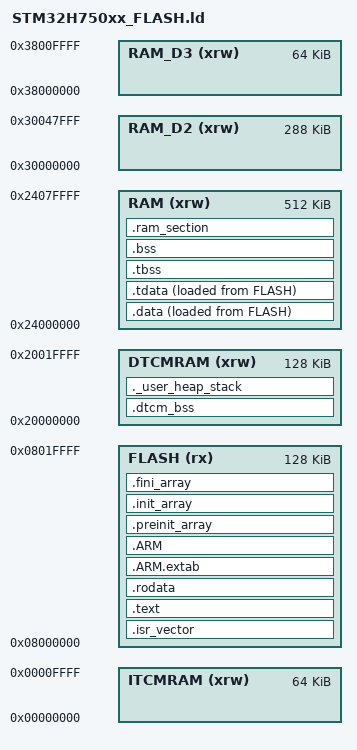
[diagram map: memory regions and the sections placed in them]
/*
******************************************************************************
**

**  File        : LinkerScript.ld
**
**  Author		: STM32CubeMX
**
**  Abstract    : Linker script for STM32H750VBTx series
**                128Kbytes FLASH and 1056Kbytes RAM
**
**                Set heap size, stack size and stack location according
**                to application requirements.
**
**                Set memory bank area and size if external memory is used.
**
**  Target      : STMicroelectronics STM32
**
**  Distribution: The file is distributed “as is,” without any warranty
**                of any kind.
**
*****************************************************************************
** @attention
**
** <h2><center>&copy; COPYRIGHT(c) 2025 STMicroelectronics</center></h2>
**
** Redistribution and use in source and binary forms, with or without modification,
** are permitted provided that the following conditions are met:
**   1. Redistributions of source code must retain the above copyright notice,
**      this list of conditions and the following disclaimer.
**   2. Redistributions in binary form must reproduce the above copyright notice,
**      this list of conditions and the following disclaimer in the documentation
**      and/or other materials provided with the distribution.
**   3. Neither the name of STMicroelectronics nor the names of its contributors
**      may be used to endorse or promote products derived from this software
**      without specific prior written permission.
**
** THIS SOFTWARE IS PROVIDED BY THE COPYRIGHT HOLDERS AND CONTRIBUTORS "AS IS"
** AND ANY EXPRESS OR IMPLIED WARRANTIES, INCLUDING, BUT NOT LIMITED TO, THE
** IMPLIED WARRANTIES OF MERCHANTABILITY AND FITNESS FOR A PARTICULAR PURPOSE ARE
** DISCLAIMED. IN NO EVENT SHALL THE COPYRIGHT HOLDER OR CONTRIBUTORS BE LIABLE
** FOR ANY DIRECT, INDIRECT, INCIDENTAL, SPECIAL, EXEMPLARY, OR CONSEQUENTIAL
** DAMAGES (INCLUDING, BUT NOT LIMITED TO, PROCUREMENT OF SUBSTITUTE GOODS OR
** SERVICES; LOSS OF USE, DATA, OR PROFITS; OR BUSINESS INTERRUPTION) HOWEVER
** CAUSED AND ON ANY THEORY OF LIABILITY, WHETHER IN CONTRACT, STRICT LIABILITY,
** OR TORT (INCLUDING NEGLIGENCE OR OTHERWISE) ARISING IN ANY WAY OUT OF THE USE
** OF THIS SOFTWARE, EVEN IF ADVISED OF THE POSSIBILITY OF SUCH DAMAGE.
**
*****************************************************************************
*/

/* Entry Point */
ENTRY(Reset_Handler)

/* Specify the memory areas */
MEMORY
{
DTCMRAM (xrw)      : ORIGIN = 0x20000000, LENGTH = 128K
RAM (xrw)      : ORIGIN = 0x24000000, LENGTH = 512K
RAM_D2 (xrw)      : ORIGIN = 0x30000000, LENGTH = 288K
RAM_D3 (xrw)      : ORIGIN = 0x38000000, LENGTH = 64K
ITCMRAM (xrw)      : ORIGIN = 0x00000000, LENGTH = 64K
FLASH (rx)      : ORIGIN = 0x8000000, LENGTH = 128K
}

/* ── 内存策略（本工程定制，勿让 CubeMX 覆盖本文件）────────────────────────────
   DTCMRAM (0x20000000, 128K) : 栈 + 堆（_estack/_sstack 见下）+ 可选的 .dtcm_bss 热点段
   RAM     (0x24000000, 512K) : **默认内存**：.data/.tdata/.tbss/.bss 以及 DMA 缓冲
                                （.ram_section）全部在这里
   RAM_D2 / RAM_D3 / ITCMRAM  : 未使用
   为什么数据段从 DTCM 搬到 AXI SRAM（RAM）：
     * SDMMC 用芯片内部 IDMA，DMA1/DMA2 也一样——它们都访问不到 DTCM，
       所以采样池(256KB)/FX池(192KB)/音频缓冲只能放 AXI SRAM（见 .ram_section 段）；
     * .bss 一起搬过去后，DTCM 的 128KB 整块留给栈和显式标注的热点数组
       （用 SYNTH_HOT / section(".dtcm_bss") 标注，见 .dtcm_bss 段）。 */

/* Highest address of the user mode stack */
_estack = ORIGIN(DTCMRAM) + LENGTH(DTCMRAM);    /* end of RAM */
_sstack = _estack - _Min_Stack_Size;
/* Generate a link error if heap and stack don't fit into RAM */
_Min_Heap_Size = 0x200;      /* required amount of heap  */
_Min_Stack_Size = 0x2000; /* required amount of stack */

/* Define output sections */
SECTIONS
{
  /* The startup code goes first into FLASH */
  .isr_vector :
  {
    . = ALIGN(4);
    KEEP(*(.isr_vector)) /* Startup code */
    . = ALIGN(4);
  } >FLASH

  /* The program code and other data goes into FLASH */
  .text :
  {
    . = ALIGN(4);
    *(.text)           /* .text sections (code) */
    *(.text*)          /* .text* sections (code) */
    *(.glue_7)         /* glue arm to thumb code */
    *(.glue_7t)        /* glue thumb to arm code */
    *(.eh_frame)

    KEEP (*(.init))
    KEEP (*(.fini))

    . = ALIGN(4);
    _etext = .;        /* define a global symbols at end of code */
  } >FLASH

  /* Constant data goes into FLASH */
  .rodata :
  {
    . = ALIGN(4);
    *(.rodata)         /* .rodata sections (constants, strings, etc.) */
    *(.rodata*)        /* .rodata* sections (constants, strings, etc.) */
    . = ALIGN(4);
  } >FLASH

  .ARM.extab (READONLY) : /* The "READONLY" keyword is only supported in GCC11 and later, remove it if using GCC10 or earlier. */
  {
    . = ALIGN(4);
    *(.ARM.extab* .gnu.linkonce.armextab.*)
    . = ALIGN(4);
  } >FLASH

  .ARM (READONLY) : /* The "READONLY" keyword is only supported in GCC11 and later, remove it if using GCC10 or earlier. */
  {
    . = ALIGN(4);
    __exidx_start = .;
    *(.ARM.exidx*)
    __exidx_end = .;
    . = ALIGN(4);
  } >FLASH

  .preinit_array (READONLY) : /* The "READONLY" keyword is only supported in GCC11 and later, remove it if using GCC10 or earlier. */
  {
    . = ALIGN(4);
    PROVIDE_HIDDEN (__preinit_array_start = .);
    KEEP (*(.preinit_array*))
    PROVIDE_HIDDEN (__preinit_array_end = .);
    . = ALIGN(4);
  } >FLASH

  .init_array (READONLY) : /* The "READONLY" keyword is only supported in GCC11 and later, remove it if using GCC10 or earlier. */
  {
    . = ALIGN(4);
    PROVIDE_HIDDEN (__init_array_start = .);
    KEEP (*(SORT(.init_array.*)))
    KEEP (*(.init_array*))
    PROVIDE_HIDDEN (__init_array_end = .);
    . = ALIGN(4);
  } >FLASH

  .fini_array (READONLY) : /* The "READONLY" keyword is only supported in GCC11 and later, remove it if using GCC10 or earlier. */
  {
    . = ALIGN(4);
    PROVIDE_HIDDEN (__fini_array_start = .);
    KEEP (*(SORT(.fini_array.*)))
    KEEP (*(.fini_array*))
    PROVIDE_HIDDEN (__fini_array_end = .);
    . = ALIGN(4);
  } >FLASH

  /* used by the startup to initialize data */
  _sidata = LOADADDR(.data);

  /* Initialized data sections goes into RAM, load LMA copy after code */
  .data :
  {
    . = ALIGN(4);
    _sdata = .;        /* create a global symbol at data start */
    *(.data)           /* .data sections */
    *(.data*)          /* .data* sections */
    *(.RamFunc)        /* .RamFunc sections */
    *(.RamFunc*)       /* .RamFunc* sections */

    . = ALIGN(4);
  } >RAM AT> FLASH

 /* Initialized TLS data section */
  .tdata : ALIGN(4)
  {
    *(.tdata .tdata.* .gnu.linkonce.td.*)
    . = ALIGN(4);
    _edata = .;        /* define a global symbol at data end */
    PROVIDE(__data_end = .);
    PROVIDE(__tdata_end = .);
  } >RAM AT> FLASH

  PROVIDE( __tdata_start = ADDR(.tdata) );
  PROVIDE( __tdata_size = __tdata_end - __tdata_start );

  PROVIDE( __data_start = ADDR(.data) );
  PROVIDE( __data_size = __data_end - __data_start );

  PROVIDE( __tdata_source = LOADADDR(.tdata) );
  PROVIDE( __tdata_source_end = LOADADDR(.tdata) + SIZEOF(.tdata) );
  PROVIDE( __tdata_source_size = __tdata_source_end - __tdata_source );

  PROVIDE( __data_source = LOADADDR(.data) );
  PROVIDE( __data_source_end = __tdata_source_end );
  PROVIDE( __data_source_size = __data_source_end - __data_source );
  /* Uninitialized data section */
  .tbss (NOLOAD) : ALIGN(4)
  {
     /* This is used by the startup in order to initialize the .bss secion */
    _sbss = .;         /* define a global symbol at bss start */
    __bss_start__ = _sbss;
    *(.tbss .tbss.*)
    . = ALIGN(4);
    PROVIDE( __tbss_end = . );
  } >RAM

  PROVIDE( __tbss_start = ADDR(.tbss) );
  PROVIDE( __tbss_size = __tbss_end - __tbss_start );
  PROVIDE( __tbss_offset = ADDR(.tbss) - ADDR(.tdata) );

  PROVIDE( __tls_base = __tdata_start );
  PROVIDE( __tls_end = __tbss_end );
  PROVIDE( __tls_size = __tls_end - __tls_base );
  PROVIDE( __tls_align = MAX(ALIGNOF(.tdata), ALIGNOF(.tbss)) );
  PROVIDE( __tls_size_align = (__tls_size + __tls_align - 1) & ~(__tls_align - 1) );
  PROVIDE( __arm32_tls_tcb_offset = MAX(8, __tls_align) );
  PROVIDE( __arm64_tls_tcb_offset = MAX(16, __tls_align) );

  .bss (NOLOAD) : ALIGN(4)
  {
    *(.bss)
    *(.bss*)
    *(COMMON)

      . = ALIGN(4);
    _ebss = .;         /* define a global symbol at bss end */
    __bss_end__ = _ebss;
      PROVIDE( __bss_end = .);
  } >RAM
  PROVIDE( __non_tls_bss_start = ADDR(.bss) );

  PROVIDE( __bss_start = __tbss_start );
  PROVIDE( __bss_size = __bss_end - __bss_start );

  /* ── DTCM 热点段（可选）────────────────────────────────────────────────────
     本文件的默认策略：**所有 .data/.bss 放 AXI SRAM（RAM, 0x24000000），DTCM 只留给
     栈、堆和显式标注的热点**。给变量加属性即可搬进 DTCM（128KB，与 CPU 同频零等待，
     比 AXI SRAM 少一层总线矩阵延迟）：

         #define SYNTH_HOT __attribute__((section(".dtcm_bss")))
         SYNTH_HOT float SineTable::table_[SineTable::kSize];

     两条约束：
       * 本段是 NOLOAD（不占 flash、启动代码也不清零），所以只放“运行期由 Init() 填、
         不依赖静态构造”的数组；清零由 Core/Src/main.c 的 App_ZeroDtcmBss() 在 main 里做。
       * DMA1/DMA2 访问不到 DTCM——DMA 缓冲必须留在下面的 .ram_section（AXI SRAM）。 */
  .dtcm_bss (NOLOAD) : ALIGN(32)
  {
    . = ALIGN(32);
    __dtcm_bss_start = .;
    *(.dtcm_bss)
    *(.dtcm_bss*)
    . = ALIGN(32);
    __dtcm_bss_end = .;
  } >DTCMRAM

  /* 应用层 DMA / 大缓冲专用段（AXI SRAM 512KB）：
       audio_out_sai.c 的音频 DMA 半缓冲、fx_memory.cpp 的 FX 池、ROMpler 采样池。
     为什么必须单独一段：
       * DMA1/DMA2 访问不到 DTCM（0x20000000），这些缓冲放 DTCM 会传输失败；
       * NOLOAD => 不生成 FLASH 里的初值（否则 456KB 的缓冲根本塞不进 128KB flash），
         也不参与启动清零，所以放进来的数组必须自己保证“用前先写”。
     注意：AXI SRAM 是 Cacheable 的，DMA 写/读前后的 cache 维护见 audio_out_sai.c。 */
  .ram_section (NOLOAD) : ALIGN(32)
  {
    . = ALIGN(32);
    __ram_section_start = .;
    *(.ram_section)
    *(.ram_section*)
    . = ALIGN(32);
    __ram_section_end = .;
  } >RAM

  /* User_heap_stack section, used to check that there is enough RAM left */
  ._user_heap_stack (NOLOAD) :
  {
    . = ALIGN(8);
    PROVIDE ( end = . );
    PROVIDE ( _end = . );
    . = . + _Min_Heap_Size;
    . = . + _Min_Stack_Size;
    . = ALIGN(8);
  } >DTCMRAM



  /* 注意：CubeMX 默认会在这里丢弃 libc.a / libm.a / libgcc.a 的全部成员：
       /DISCARD/ : { libc.a:*(*) libm.a:*(*) libgcc.a:*(*) }
     对本工程是致命的——C++ 运行时（__libc_init_array/全局构造）、memset/memcpy、
     软浮点与 __aeabi_* 助手全在这些库里。因此这三行已删除，请勿让 CubeMX 重新生成覆盖本文件。 */

}
